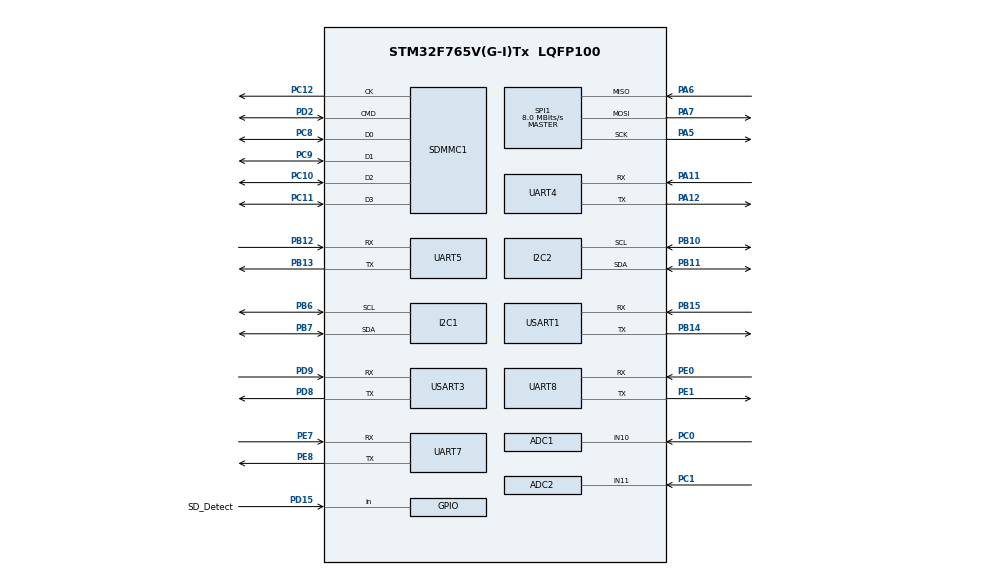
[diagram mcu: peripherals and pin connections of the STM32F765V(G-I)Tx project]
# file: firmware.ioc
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ADC1.Channel-0\#ChannelRegularConversion=ADC_CHANNEL_10
ADC1.NbrOfConversionFlag=1
ADC1.Rank-0\#ChannelRegularConversion=1
ADC1.SamplingTime-0\#ChannelRegularConversion=ADC_SAMPLETIME_480CYCLES
ADC1.master=1
ADC2.Channel-0\#ChannelRegularConversion=ADC_CHANNEL_11
ADC2.NbrOfConversionFlag=1
ADC2.Rank-0\#ChannelRegularConversion=1
ADC2.SamplingTime-0\#ChannelRegularConversion=ADC_SAMPLETIME_480CYCLES
CORTEX_M7.default_mode_Activation=1
FATFS.BSP.number=1
FATFS._USE_LFN=2
FATFS0.BSP.STBoard=false
FATFS0.BSP.api=Unknown
FATFS0.BSP.instance=PD15
FATFS0.BSP.ip=GPIO
FATFS0.BSP.mode=Input
FATFS0.BSP.name=Detect_SDIO
FATFS0.BSP.solution=PD15
FREERTOS.Tasks01=defaultTask,24,512,StartDefaultTask,Default,NULL,Dynamic,NULL,NULL
Mcu.Family=STM32F7
Mcu.Name=STM32F765V(G-I)Tx
Mcu.Package=LQFP100
NVIC.PriorityGroup=NVIC_PRIORITYGROUP_4
NVIC.SDMMC1_IRQn=true\:5\:0\:false\:false\:true\:true\:true\:true\:true
NVIC.TIM1_UP_TIM10_IRQn=true\:15\:0\:false\:false\:true\:false\:false\:true\:true
NVIC.TimeBase=TIM1_UP_TIM10_IRQn
NVIC.TimeBaseIP=TIM1
PC0.Signal=ADCx_IN10
PC1.Signal=ADCx_IN11
PA11.Mode=Asynchronous
PA11.Signal=UART4_RX
PA12.Mode=Asynchronous
PA12.Signal=UART4_TX
PA13.Mode=Trace_Asynchronous_SW
PA13.Signal=SYS_JTMS-SWDIO
PA14.Mode=Trace_Asynchronous_SW
PA14.Signal=SYS_JTCK-SWCLK
PA5.Mode=Full_Duplex_Master
PA5.Signal=SPI1_SCK
PA6.Mode=Full_Duplex_Master
PA6.Signal=SPI1_MISO
PA7.Mode=Full_Duplex_Master
PA7.Signal=SPI1_MOSI
PB10.Mode=I2C
PB10.Signal=I2C2_SCL
PB11.Mode=I2C
PB11.Signal=I2C2_SDA
PB12.Mode=Asynchronous
PB12.Signal=UART5_RX
PB13.Mode=Asynchronous
PB13.Signal=UART5_TX
PB14.Mode=Asynchronous
PB14.Signal=USART1_TX
PB15.Mode=Asynchronous
PB15.Signal=USART1_RX
PB3.Mode=Trace_Asynchronous_SW
PB3.Signal=SYS_JTDO-SWO
PB6.Mode=I2C
PB6.Signal=I2C1_SCL
PB7.Mode=I2C
PB7.Signal=I2C1_SDA
PC10.Mode=SD_4_bits_Wide_bus
PC10.Signal=SDMMC1_D2
PC11.Mode=SD_4_bits_Wide_bus
PC11.Signal=SDMMC1_D3
PC12.Mode=SD_4_bits_Wide_bus
PC12.Signal=SDMMC1_CK
PC6.GPIO_Label=LED
PC6.Signal=S_TIM3_CH1
PC8.Mode=SD_4_bits_Wide_bus
PC8.Signal=SDMMC1_D0
PC9.Mode=SD_4_bits_Wide_bus
PC9.Signal=SDMMC1_D1
PD12.GPIO_Label=THRR
PD12.Signal=S_TIM4_CH1
PD13.GPIO_Label=THRL
PD13.Signal=S_TIM4_CH2
PD15.GPIO_Label=SD_Detect
PD15.Signal=GPIO_Input
PD2.Mode=SD_4_bits_Wide_bus
PD2.Signal=SDMMC1_CMD
PD8.Mode=Asynchronous
PD8.Signal=USART3_TX
PD9.Mode=Asynchronous
PD9.Signal=USART3_RX
PE0.Mode=Asynchronous
PE0.Signal=UART8_RX
PE1.Mode=Asynchronous
PE1.Signal=UART8_TX
PE7.Mode=Asynchronous
PE7.Signal=UART7_RX
PE8.Mode=Asynchronous
PE8.Signal=UART7_TX
ProjectManager.HeapSize=0x200
ProjectManager.StackSize=0x400
ProjectManager.TargetToolchain=CMake
RCC.HSE_VALUE=25000000
RCC.HSI_VALUE=16000000
RCC.LSE_VALUE=32768
RCC.PLLM=8
RCC.PLLN=96
RCC.PLLQ=4
RCC.USBFreq_Value=48000000
RCC.VCOOutputFreq_Value=192000000
SDMMC1.ClockDiv=4
SH.ADCx_IN10.0=ADC1_IN10,IN10
SH.ADCx_IN11.0=ADC2_IN11,IN11
SH.S_TIM3_CH1.0=TIM3_CH1
SH.S_TIM4_CH1.0=TIM4_CH1
SH.S_TIM4_CH2.0=TIM4_CH2
SPI1.CalculateBaudRate=8.0 MBits/s
SPI1.DataSize=SPI_DATASIZE_8BIT
SPI1.Direction=SPI_DIRECTION_2LINES
SPI1.Mode=SPI_MODE_MASTER
SPI1.VirtualType=VM_MASTER
USART1.VirtualMode-Asynchronous=VM_ASYNC
USART3.VirtualMode-Asynchronous=VM_ASYNC
VP_FATFS_VS_SDIO.Mode=SDIO
VP_FREERTOS_VS_CMSIS_V2.Mode=CMSIS_V2
VP_RNG_VS_RNG.Mode=RNG_Activate
VP_SYS_VS_tim1.Mode=TIM1
board=custom

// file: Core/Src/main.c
/* USER CODE BEGIN Header */
/**
  ******************************************************************************
  * @file           : main.c
  * @brief          : Main program body
  ******************************************************************************
  * @attention
  *
  * Copyright (c) 2026 STMicroelectronics.
  * All rights reserved.
  *
  * This software is licensed under terms that can be found in the LICENSE file
  * in the root directory of this software component.
  * If no LICENSE file comes with this software, it is provided AS-IS.
  *
  ******************************************************************************
  */
/* USER CODE END Header */
#include "main.h"
#include "cmsis_os.h"
#include "fatfs.h"

/* USER CODE BEGIN Includes */
#include "app_sensors.h"
/* USER CODE END Includes */

ADC_HandleTypeDef hadc1;
ADC_HandleTypeDef hadc2;

I2C_HandleTypeDef hi2c1;
I2C_HandleTypeDef hi2c2;

RNG_HandleTypeDef hrng;

SD_HandleTypeDef hsd1;

SPI_HandleTypeDef hspi1;

UART_HandleTypeDef huart4;
UART_HandleTypeDef huart5;
UART_HandleTypeDef huart7;
UART_HandleTypeDef huart8;
UART_HandleTypeDef huart1;
UART_HandleTypeDef huart3;

/* Definitions for defaultTask */
osThreadId_t defaultTaskHandle;
const osThreadAttr_t defaultTask_attributes = {
  .name = "defaultTask",
  .stack_size = 512 * 4,
  .priority = (osPriority_t) osPriorityNormal,
};

void SystemClock_Config(void);
static void MPU_Config(void);
static void MX_GPIO_Init(void);
static void MX_ADC1_Init(void);
static void MX_ADC2_Init(void);
static void MX_I2C1_Init(void);
static void MX_I2C2_Init(void);
static void MX_RNG_Init(void);
static void MX_SDMMC1_SD_Init(void);
static void MX_SPI1_Init(void);
static void MX_UART4_Init(void);
static void MX_UART5_Init(void);
static void MX_UART7_Init(void);
static void MX_UART8_Init(void);
static void MX_USART1_UART_Init(void);
static void MX_USART3_UART_Init(void);
void StartDefaultTask(void *argument);

int main(void)
{

  /* MPU Configuration--------------------------------------------------------*/
  MPU_Config();

  /* MCU Configuration--------------------------------------------------------*/

  /* Reset of all peripherals, Initializes the Flash interface and the Systick. */
  HAL_Init();

  /* Configure the system clock */
  SystemClock_Config();

  /* Initialize all configured peripherals */
  MX_GPIO_Init();
  MX_ADC1_Init();
  MX_ADC2_Init();
  MX_I2C1_Init();
  MX_I2C2_Init();
  MX_RNG_Init();
  MX_SDMMC1_SD_Init();
  MX_SPI1_Init();
  MX_UART4_Init();
  MX_UART5_Init();
  MX_UART7_Init();
  MX_UART8_Init();
  MX_USART1_UART_Init();
  MX_USART3_UART_Init();
  MX_FATFS_Init();

  /* Init scheduler */
  osKernelInitialize();

  /* Create the thread(s) */
  /* creation of defaultTask */
  defaultTaskHandle = osThreadNew(StartDefaultTask, NULL, &defaultTask_attributes);

  /* Start scheduler */
  osKernelStart();

  /* We should never get here as control is now taken by the scheduler */

  /* Infinite loop */
  while (1)
  {

  }
}

void SystemClock_Config(void)
{
  RCC_OscInitTypeDef RCC_OscInitStruct = {0};
  RCC_ClkInitTypeDef RCC_ClkInitStruct = {0};

  /** Configure the main internal regulator output voltage
  */
  __HAL_RCC_PWR_CLK_ENABLE();
  __HAL_PWR_VOLTAGESCALING_CONFIG(PWR_REGULATOR_VOLTAGE_SCALE3);

  /** Initializes the RCC Oscillators according to the specified parameters
  * in the RCC_OscInitTypeDef structure.
  */
  RCC_OscInitStruct.OscillatorType = RCC_OSCILLATORTYPE_HSI;
  RCC_OscInitStruct.HSIState = RCC_HSI_ON;
  RCC_OscInitStruct.HSICalibrationValue = RCC_HSICALIBRATION_DEFAULT;
  RCC_OscInitStruct.PLL.PLLState = RCC_PLL_ON;
  RCC_OscInitStruct.PLL.PLLSource = RCC_PLLSOURCE_HSI;
  RCC_OscInitStruct.PLL.PLLM = 8;
  RCC_OscInitStruct.PLL.PLLN = 96;
  RCC_OscInitStruct.PLL.PLLP = RCC_PLLP_DIV2;
  RCC_OscInitStruct.PLL.PLLQ = 4;
  RCC_OscInitStruct.PLL.PLLR = 2;
  if (HAL_RCC_OscConfig(&RCC_OscInitStruct) != HAL_OK)
  {
    Error_Handler();
  }

  /** Initializes the CPU, AHB and APB buses clocks
  */
  RCC_ClkInitStruct.ClockType = RCC_CLOCKTYPE_HCLK|RCC_CLOCKTYPE_SYSCLK
                              |RCC_CLOCKTYPE_PCLK1|RCC_CLOCKTYPE_PCLK2;
  RCC_ClkInitStruct.SYSCLKSource = RCC_SYSCLKSOURCE_HSI;
  RCC_ClkInitStruct.AHBCLKDivider = RCC_SYSCLK_DIV1;
  RCC_ClkInitStruct.APB1CLKDivider = RCC_HCLK_DIV1;
  RCC_ClkInitStruct.APB2CLKDivider = RCC_HCLK_DIV1;

  if (HAL_RCC_ClockConfig(&RCC_ClkInitStruct, FLASH_LATENCY_0) != HAL_OK)
  {
    Error_Handler();
  }
}

static void MX_ADC1_Init(void)
{

  ADC_ChannelConfTypeDef sConfig = {0};

  /** Configure the global features of the ADC (Clock, Resolution, Data Alignment and number of conversion)
  */
  hadc1.Instance = ADC1;
  hadc1.Init.ClockPrescaler = ADC_CLOCK_SYNC_PCLK_DIV2;
  hadc1.Init.Resolution = ADC_RESOLUTION_12B;
  hadc1.Init.ScanConvMode = ADC_SCAN_DISABLE;
  hadc1.Init.ContinuousConvMode = DISABLE;
  hadc1.Init.DiscontinuousConvMode = DISABLE;
  hadc1.Init.ExternalTrigConvEdge = ADC_EXTERNALTRIGCONVEDGE_NONE;
  hadc1.Init.ExternalTrigConv = ADC_SOFTWARE_START;
  hadc1.Init.DataAlign = ADC_DATAALIGN_RIGHT;
  hadc1.Init.NbrOfConversion = 1;
  hadc1.Init.DMAContinuousRequests = DISABLE;
  hadc1.Init.EOCSelection = ADC_EOC_SINGLE_CONV;
  if (HAL_ADC_Init(&hadc1) != HAL_OK)
  {
    Error_Handler();
  }

  /** Configure for the selected ADC regular channel its corresponding rank in the sequencer and its sample time.
  */
  sConfig.Channel = ADC_CHANNEL_10;
  sConfig.Rank = ADC_REGULAR_RANK_1;
  sConfig.SamplingTime = ADC_SAMPLETIME_480CYCLES;
  if (HAL_ADC_ConfigChannel(&hadc1, &sConfig) != HAL_OK)
  {
    Error_Handler();
  }

}

static void MX_ADC2_Init(void)
{

  ADC_ChannelConfTypeDef sConfig = {0};

  /** Configure the global features of the ADC (Clock, Resolution, Data Alignment and number of conversion)
  */
  hadc2.Instance = ADC2;
  hadc2.Init.ClockPrescaler = ADC_CLOCK_SYNC_PCLK_DIV2;
  hadc2.Init.Resolution = ADC_RESOLUTION_12B;
  hadc2.Init.ScanConvMode = ADC_SCAN_DISABLE;
  hadc2.Init.ContinuousConvMode = DISABLE;
  hadc2.Init.DiscontinuousConvMode = DISABLE;
  hadc2.Init.ExternalTrigConvEdge = ADC_EXTERNALTRIGCONVEDGE_NONE;
  hadc2.Init.ExternalTrigConv = ADC_SOFTWARE_START;
  hadc2.Init.DataAlign = ADC_DATAALIGN_RIGHT;
  hadc2.Init.NbrOfConversion = 1;
  hadc2.Init.DMAContinuousRequests = DISABLE;
  hadc2.Init.EOCSelection = ADC_EOC_SINGLE_CONV;
  if (HAL_ADC_Init(&hadc2) != HAL_OK)
  {
    Error_Handler();
  }

  /** Configure for the selected ADC regular channel its corresponding rank in the sequencer and its sample time.
  */
  sConfig.Channel = ADC_CHANNEL_11;
  sConfig.Rank = ADC_REGULAR_RANK_1;
  sConfig.SamplingTime = ADC_SAMPLETIME_480CYCLES;
  if (HAL_ADC_ConfigChannel(&hadc2, &sConfig) != HAL_OK)
  {
    Error_Handler();
  }

}

static void MX_I2C1_Init(void)
{

  hi2c1.Instance = I2C1;
  hi2c1.Init.Timing = 0x00303D5B;
  hi2c1.Init.OwnAddress1 = 0;
  hi2c1.Init.AddressingMode = I2C_ADDRESSINGMODE_7BIT;
  hi2c1.Init.DualAddressMode = I2C_DUALADDRESS_DISABLE;
  hi2c1.Init.OwnAddress2 = 0;
  hi2c1.Init.OwnAddress2Masks = I2C_OA2_NOMASK;
  hi2c1.Init.GeneralCallMode = I2C_GENERALCALL_DISABLE;
  hi2c1.Init.NoStretchMode = I2C_NOSTRETCH_DISABLE;
  if (HAL_I2C_Init(&hi2c1) != HAL_OK)
  {
    Error_Handler();
  }

  /** Configure Analogue filter
  */
  if (HAL_I2CEx_ConfigAnalogFilter(&hi2c1, I2C_ANALOGFILTER_ENABLE) != HAL_OK)
  {
    Error_Handler();
  }

  /** Configure Digital filter
  */
  if (HAL_I2CEx_ConfigDigitalFilter(&hi2c1, 0) != HAL_OK)
  {
    Error_Handler();
  }

}

static void MX_I2C2_Init(void)
{

  hi2c2.Instance = I2C2;
  hi2c2.Init.Timing = 0x00303D5B;
  hi2c2.Init.OwnAddress1 = 0;
  hi2c2.Init.AddressingMode = I2C_ADDRESSINGMODE_7BIT;
  hi2c2.Init.DualAddressMode = I2C_DUALADDRESS_DISABLE;
  hi2c2.Init.OwnAddress2 = 0;
  hi2c2.Init.OwnAddress2Masks = I2C_OA2_NOMASK;
  hi2c2.Init.GeneralCallMode = I2C_GENERALCALL_DISABLE;
  hi2c2.Init.NoStretchMode = I2C_NOSTRETCH_DISABLE;
  if (HAL_I2C_Init(&hi2c2) != HAL_OK)
  {
    Error_Handler();
  }

  /** Configure Analogue filter
  */
  if (HAL_I2CEx_ConfigAnalogFilter(&hi2c2, I2C_ANALOGFILTER_ENABLE) != HAL_OK)
  {
    Error_Handler();
  }

  /** Configure Digital filter
  */
  if (HAL_I2CEx_ConfigDigitalFilter(&hi2c2, 0) != HAL_OK)
  {
    Error_Handler();
  }

}

static void MX_RNG_Init(void)
{

  hrng.Instance = RNG;
  if (HAL_RNG_Init(&hrng) != HAL_OK)
  {
    Error_Handler();
  }

}

static void MX_SDMMC1_SD_Init(void)
{

  hsd1.Instance = SDMMC1;
  hsd1.Init.ClockEdge = SDMMC_CLOCK_EDGE_RISING;
  hsd1.Init.ClockBypass = SDMMC_CLOCK_BYPASS_DISABLE;
  hsd1.Init.ClockPowerSave = SDMMC_CLOCK_POWER_SAVE_DISABLE;
  hsd1.Init.BusWide = SDMMC_BUS_WIDE_1B;
  hsd1.Init.HardwareFlowControl = SDMMC_HARDWARE_FLOW_CONTROL_DISABLE;
  hsd1.Init.ClockDiv = 4;

}

static void MX_SPI1_Init(void)
{

  /* SPI1 parameter configuration*/
  hspi1.Instance = SPI1;
  hspi1.Init.Mode = SPI_MODE_MASTER;
  hspi1.Init.Direction = SPI_DIRECTION_2LINES;
  hspi1.Init.DataSize = SPI_DATASIZE_8BIT;
  hspi1.Init.CLKPolarity = SPI_POLARITY_LOW;
  hspi1.Init.CLKPhase = SPI_PHASE_1EDGE;
  hspi1.Init.NSS = SPI_NSS_SOFT;
  hspi1.Init.BaudRatePrescaler = SPI_BAUDRATEPRESCALER_2;
  hspi1.Init.FirstBit = SPI_FIRSTBIT_MSB;
  hspi1.Init.TIMode = SPI_TIMODE_DISABLE;
  hspi1.Init.CRCCalculation = SPI_CRCCALCULATION_DISABLE;
  hspi1.Init.CRCPolynomial = 7;
  hspi1.Init.CRCLength = SPI_CRC_LENGTH_DATASIZE;
  hspi1.Init.NSSPMode = SPI_NSS_PULSE_ENABLE;
  if (HAL_SPI_Init(&hspi1) != HAL_OK)
  {
    Error_Handler();
  }

}

static void MX_UART4_Init(void)
{

  huart4.Instance = UART4;
  huart4.Init.BaudRate = 115200;
  huart4.Init.WordLength = UART_WORDLENGTH_8B;
  huart4.Init.StopBits = UART_STOPBITS_1;
  huart4.Init.Parity = UART_PARITY_NONE;
  huart4.Init.Mode = UART_MODE_TX_RX;
  huart4.Init.HwFlowCtl = UART_HWCONTROL_NONE;
  huart4.Init.OverSampling = UART_OVERSAMPLING_16;
  huart4.Init.OneBitSampling = UART_ONE_BIT_SAMPLE_DISABLE;
  huart4.AdvancedInit.AdvFeatureInit = UART_ADVFEATURE_NO_INIT;
  if (HAL_UART_Init(&huart4) != HAL_OK)
  {
    Error_Handler();
  }

}

static void MX_UART5_Init(void)
{

  huart5.Instance = UART5;
  huart5.Init.BaudRate = 115200;
  huart5.Init.WordLength = UART_WORDLENGTH_8B;
  huart5.Init.StopBits = UART_STOPBITS_1;
  huart5.Init.Parity = UART_PARITY_NONE;
  huart5.Init.Mode = UART_MODE_TX_RX;
  huart5.Init.HwFlowCtl = UART_HWCONTROL_NONE;
  huart5.Init.OverSampling = UART_OVERSAMPLING_16;
  huart5.Init.OneBitSampling = UART_ONE_BIT_SAMPLE_DISABLE;
  huart5.AdvancedInit.AdvFeatureInit = UART_ADVFEATURE_NO_INIT;
  if (HAL_UART_Init(&huart5) != HAL_OK)
  {
    Error_Handler();
  }

}

static void MX_UART7_Init(void)
{

  huart7.Instance = UART7;
  huart7.Init.BaudRate = 115200;
  huart7.Init.WordLength = UART_WORDLENGTH_8B;
  huart7.Init.StopBits = UART_STOPBITS_1;
  huart7.Init.Parity = UART_PARITY_NONE;
  huart7.Init.Mode = UART_MODE_TX_RX;
  huart7.Init.HwFlowCtl = UART_HWCONTROL_NONE;
  huart7.Init.OverSampling = UART_OVERSAMPLING_16;
  huart7.Init.OneBitSampling = UART_ONE_BIT_SAMPLE_DISABLE;
  huart7.AdvancedInit.AdvFeatureInit = UART_ADVFEATURE_NO_INIT;
  if (HAL_UART_Init(&huart7) != HAL_OK)
  {
    Error_Handler();
  }

}

static void MX_UART8_Init(void)
{

  huart8.Instance = UART8;
  huart8.Init.BaudRate = 115200;
  huart8.Init.WordLength = UART_WORDLENGTH_8B;
  huart8.Init.StopBits = UART_STOPBITS_1;
  huart8.Init.Parity = UART_PARITY_NONE;
  huart8.Init.Mode = UART_MODE_TX_RX;
  huart8.Init.HwFlowCtl = UART_HWCONTROL_NONE;
  huart8.Init.OverSampling = UART_OVERSAMPLING_16;
  huart8.Init.OneBitSampling = UART_ONE_BIT_SAMPLE_DISABLE;
  huart8.AdvancedInit.AdvFeatureInit = UART_ADVFEATURE_NO_INIT;
  if (HAL_UART_Init(&huart8) != HAL_OK)
  {
    Error_Handler();
  }

}

static void MX_USART1_UART_Init(void)
{

  huart1.Instance = USART1;
  huart1.Init.BaudRate = 115200;
  huart1.Init.WordLength = UART_WORDLENGTH_8B;
  huart1.Init.StopBits = UART_STOPBITS_1;
  huart1.Init.Parity = UART_PARITY_NONE;
  huart1.Init.Mode = UART_MODE_TX_RX;
  huart1.Init.HwFlowCtl = UART_HWCONTROL_NONE;
  huart1.Init.OverSampling = UART_OVERSAMPLING_16;
  huart1.Init.OneBitSampling = UART_ONE_BIT_SAMPLE_DISABLE;
  huart1.AdvancedInit.AdvFeatureInit = UART_ADVFEATURE_NO_INIT;
  if (HAL_UART_Init(&huart1) != HAL_OK)
  {
    Error_Handler();
  }

}

static void MX_USART3_UART_Init(void)
{

  huart3.Instance = USART3;
  huart3.Init.BaudRate = 115200;
  huart3.Init.WordLength = UART_WORDLENGTH_8B;
  huart3.Init.StopBits = UART_STOPBITS_1;
  huart3.Init.Parity = UART_PARITY_NONE;
  huart3.Init.Mode = UART_MODE_TX_RX;
  huart3.Init.HwFlowCtl = UART_HWCONTROL_NONE;
  huart3.Init.OverSampling = UART_OVERSAMPLING_16;
  huart3.Init.OneBitSampling = UART_ONE_BIT_SAMPLE_DISABLE;
  huart3.AdvancedInit.AdvFeatureInit = UART_ADVFEATURE_NO_INIT;
  if (HAL_UART_Init(&huart3) != HAL_OK)
  {
    Error_Handler();
  }

}

static void MX_GPIO_Init(void)
{
  GPIO_InitTypeDef GPIO_InitStruct = {0};

  /* GPIO Ports Clock Enable */
  __HAL_RCC_GPIOA_CLK_ENABLE();
  __HAL_RCC_GPIOE_CLK_ENABLE();
  __HAL_RCC_GPIOB_CLK_ENABLE();
  __HAL_RCC_GPIOD_CLK_ENABLE();
  __HAL_RCC_GPIOC_CLK_ENABLE();

  /*Configure GPIO pins : THRR_Pin THRL_Pin */
  GPIO_InitStruct.Pin = THRR_Pin|THRL_Pin;
  GPIO_InitStruct.Mode = GPIO_MODE_AF_PP;
  GPIO_InitStruct.Pull = GPIO_NOPULL;
  GPIO_InitStruct.Speed = GPIO_SPEED_FREQ_LOW;
  GPIO_InitStruct.Alternate = GPIO_AF2_TIM4;
  HAL_GPIO_Init(GPIOD, &GPIO_InitStruct);

  /*Configure GPIO pin : SD_Detect_Pin */
  GPIO_InitStruct.Pin = SD_Detect_Pin;
  GPIO_InitStruct.Mode = GPIO_MODE_INPUT;
  GPIO_InitStruct.Pull = GPIO_NOPULL;
  HAL_GPIO_Init(SD_Detect_GPIO_Port, &GPIO_InitStruct);

  /*Configure GPIO pin : LED_Pin */
  GPIO_InitStruct.Pin = LED_Pin;
  GPIO_InitStruct.Mode = GPIO_MODE_AF_PP;
  GPIO_InitStruct.Pull = GPIO_NOPULL;
  GPIO_InitStruct.Speed = GPIO_SPEED_FREQ_LOW;
  GPIO_InitStruct.Alternate = GPIO_AF2_TIM3;
  HAL_GPIO_Init(LED_GPIO_Port, &GPIO_InitStruct);

}

void StartDefaultTask(void *argument)
{
  /* USER CODE BEGIN 5 */

  // Initialize all sensors and SD Card
  AppSensors_Init();

  /* Infinite loop */
  for(;;)
  {
    // Read sensors and log data continuously
    AppSensors_Task();

    osDelay(1); // Small delay to yield execution to other RTOS threads if necessary
  }
  /* USER CODE END 5 */
}

 /* MPU Configuration */

void MPU_Config(void)
{
  MPU_Region_InitTypeDef MPU_InitStruct = {0};

  /* Disables the MPU */
  HAL_MPU_Disable();

  /** Initializes and configures the Region and the memory to be protected
  */
  MPU_InitStruct.Enable = MPU_REGION_ENABLE;
  MPU_InitStruct.Number = MPU_REGION_NUMBER0;
  MPU_InitStruct.BaseAddress = 0x0;
  MPU_InitStruct.Size = MPU_REGION_SIZE_4GB;
  MPU_InitStruct.SubRegionDisable = 0x87;
  MPU_InitStruct.TypeExtField = MPU_TEX_LEVEL0;
  MPU_InitStruct.AccessPermission = MPU_REGION_NO_ACCESS;
  MPU_InitStruct.DisableExec = MPU_INSTRUCTION_ACCESS_DISABLE;
  MPU_InitStruct.IsShareable = MPU_ACCESS_SHAREABLE;
  MPU_InitStruct.IsCacheable = MPU_ACCESS_NOT_CACHEABLE;
  MPU_InitStruct.IsBufferable = MPU_ACCESS_NOT_BUFFERABLE;

  HAL_MPU_ConfigRegion(&MPU_InitStruct);
  /* Enables the MPU */
  HAL_MPU_Enable(MPU_PRIVILEGED_DEFAULT);

}

void HAL_TIM_PeriodElapsedCallback(TIM_HandleTypeDef *htim)
{
  if (htim->Instance == TIM1)
  {
    HAL_IncTick();
  }
}

void Error_Handler(void)
{
  __disable_irq();
  while (1)
  {
  }
}
